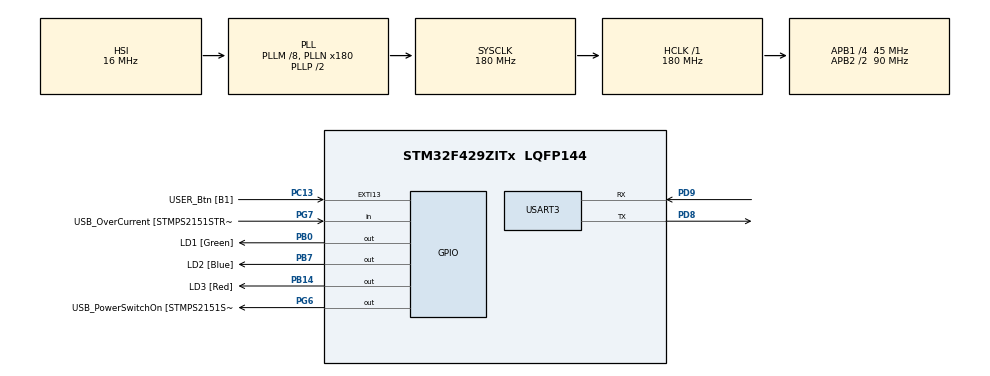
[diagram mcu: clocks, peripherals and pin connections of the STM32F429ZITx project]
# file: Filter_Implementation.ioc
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Dma.Request0=USART3_TX
Dma.Request1=USART3_RX
Dma.USART3_RX.1.Direction=DMA_PERIPH_TO_MEMORY
Dma.USART3_RX.1.FIFOMode=DMA_FIFOMODE_DISABLE
Dma.USART3_RX.1.Instance=DMA1_Stream1
Dma.USART3_RX.1.MemDataAlignment=DMA_MDATAALIGN_BYTE
Dma.USART3_RX.1.MemInc=DMA_MINC_ENABLE
Dma.USART3_RX.1.Mode=DMA_NORMAL
Dma.USART3_RX.1.PeriphDataAlignment=DMA_PDATAALIGN_BYTE
Dma.USART3_RX.1.PeriphInc=DMA_PINC_DISABLE
Dma.USART3_RX.1.Priority=DMA_PRIORITY_LOW
Dma.USART3_TX.0.Direction=DMA_MEMORY_TO_PERIPH
Dma.USART3_TX.0.FIFOMode=DMA_FIFOMODE_DISABLE
Dma.USART3_TX.0.Instance=DMA1_Stream3
Dma.USART3_TX.0.MemDataAlignment=DMA_MDATAALIGN_BYTE
Dma.USART3_TX.0.MemInc=DMA_MINC_ENABLE
Dma.USART3_TX.0.Mode=DMA_NORMAL
Dma.USART3_TX.0.PeriphDataAlignment=DMA_PDATAALIGN_BYTE
Dma.USART3_TX.0.PeriphInc=DMA_PINC_DISABLE
Dma.USART3_TX.0.Priority=DMA_PRIORITY_LOW
Mcu.Family=STM32F4
Mcu.Name=STM32F429ZITx
Mcu.Package=LQFP144
NVIC.DMA1_Stream1_IRQn=true\:0\:0\:false\:false\:true\:false\:true\:true
NVIC.DMA1_Stream3_IRQn=true\:0\:0\:false\:false\:true\:false\:true\:true
NVIC.PriorityGroup=NVIC_PRIORITYGROUP_4
NVIC.TIM1_UP_TIM10_IRQn=true\:0\:0\:false\:false\:true\:true\:true\:true
NVIC.USART3_IRQn=true\:0\:0\:false\:false\:true\:true\:true\:true
PB0.GPIO_Label=LD1 [Green]
PB0.Signal=GPIO_Output
PB14.GPIO_Label=LD3 [Red]
PB14.Signal=GPIO_Output
PB7.GPIO_Label=LD2 [Blue]
PB7.Signal=GPIO_Output
PC13.GPIO_Label=USER_Btn [B1]
PC13.Signal=GPXTI13
PD8.Mode=Asynchronous
PD8.Signal=USART3_TX
PD9.Mode=Asynchronous
PD9.Signal=USART3_RX
PG6.GPIO_Label=USB_PowerSwitchOn [STMPS2151STR_EN]
PG6.Signal=GPIO_Output
PG7.GPIO_Label=USB_OverCurrent [STMPS2151STR_FAULT]
PG7.Signal=GPIO_Input
ProjectManager.HeapSize=0x200
ProjectManager.StackSize=0x400
ProjectManager.TargetToolchain=STM32CubeIDE
RCC.48MHZClocksFreq_Value=90000000
RCC.AHBFreq_Value=180000000
RCC.APB1CLKDivider=RCC_HCLK_DIV4
RCC.APB1Freq_Value=45000000
RCC.APB1TimFreq_Value=90000000
RCC.APB2CLKDivider=RCC_HCLK_DIV2
RCC.APB2Freq_Value=90000000
RCC.APB2TimFreq_Value=180000000
RCC.CortexFreq_Value=180000000
RCC.HCLKFreq_Value=180000000
RCC.HSE_VALUE=8000000
RCC.HSI_VALUE=16000000
RCC.LSE_VALUE=32768
RCC.PLLM=8
RCC.PLLMUL=RCC_PLL_MUL9
RCC.PLLN=180
RCC.PRESCALERUSB=RCC_USBCLKSOURCE_PLL_DIV1_5
RCC.SYSCLKFreq_VALUE=180000000
RCC.SYSCLKSource=RCC_SYSCLKSOURCE_PLLCLK
RCC.SYSCLKSourceVirtual=RCC_SYSCLKSOURCE_PLLCLK
RCC.USBFreq_Value=48000000
RCC.VCOOutputFreq_Value=360000000
TIM1.AutoReloadPreload=TIM_AUTORELOAD_PRELOAD_ENABLE
TIM1.Period=1800 - 1
USART3.VirtualMode=VM_ASYNC
VP_TIM1_VS_ClockSourceINT.Mode=Internal
board=NUCLEO-F429ZI

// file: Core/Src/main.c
/* USER CODE BEGIN Header */
/**
  ******************************************************************************
  * @file           : main.c
  * @brief          : Main program body
  ******************************************************************************
  * @attention
  *
  * Copyright (c) 2025 STMicroelectronics.
  * All rights reserved.
  *
  * This software is licensed under terms that can be found in the LICENSE file
  * in the root directory of this software component.
  * If no LICENSE file comes with this software, it is provided AS-IS.
  *
  ******************************************************************************
  */
/* USER CODE END Header */
#include "main.h"

/* USER CODE BEGIN Includes */
#include <stdio.h>
#include <math.h>
#include "sfra.h"
#include "filter.h"

/* USER CODE END Includes */

TIM_HandleTypeDef htim1;

UART_HandleTypeDef huart3;
DMA_HandleTypeDef hdma_usart3_tx;
DMA_HandleTypeDef hdma_usart3_rx;

void SystemClock_Config(void);
static void MX_GPIO_Init(void);
static void MX_DMA_Init(void);
static void MX_USART3_UART_Init(void);
static void MX_TIM1_Init(void);

int main(void)
{

  /* MCU Configuration--------------------------------------------------------*/

  /* Reset of all peripherals, Initializes the Flash interface and the Systick. */
  HAL_Init();

  /* Configure the system clock */
  SystemClock_Config();

  /* Initialize all configured peripherals */
  MX_GPIO_Init();
  MX_DMA_Init();
  MX_USART3_UART_Init();
  MX_TIM1_Init();
  /* USER CODE BEGIN 2 */

//  lpf_init(ac_lpf_p, 200.0f, 100e3f);
//  pi_init(ac_pi_p, 2.0f, 500.0f, 100e3f);
//  pd_init(ac_pd_p, 2.0f, 0.002f, 100e3f);
//  sfra_init(100e3f, 5.0f, 1.54119f, 10.0f);
  sec_order_init(ac_2nd_p, 1000.0f, 0.707f, 100e3f);

  HAL_TIM_Base_Start_IT(&htim1);
  HAL_Delay(1000);
  HAL_UART_Receive_DMA(&huart3, rx_buffer, 3U);
  /* USER CODE END 2 */

  /* Infinite loop */
  /* USER CODE BEGIN WHILE */
  while (1)
  {
	  sfra_update();
    /* USER CODE END WHILE */

  }
}

void SystemClock_Config(void)
{
  RCC_OscInitTypeDef RCC_OscInitStruct = {0};
  RCC_ClkInitTypeDef RCC_ClkInitStruct = {0};

  /** Configure the main internal regulator output voltage
  */
  __HAL_RCC_PWR_CLK_ENABLE();
  __HAL_PWR_VOLTAGESCALING_CONFIG(PWR_REGULATOR_VOLTAGE_SCALE1);

  /** Initializes the RCC Oscillators according to the specified parameters
  * in the RCC_OscInitTypeDef structure.
  */
  RCC_OscInitStruct.OscillatorType = RCC_OSCILLATORTYPE_HSI;
  RCC_OscInitStruct.HSIState = RCC_HSI_ON;
  RCC_OscInitStruct.HSICalibrationValue = RCC_HSICALIBRATION_DEFAULT;
  RCC_OscInitStruct.PLL.PLLState = RCC_PLL_ON;
  RCC_OscInitStruct.PLL.PLLSource = RCC_PLLSOURCE_HSI;
  RCC_OscInitStruct.PLL.PLLM = 8;
  RCC_OscInitStruct.PLL.PLLN = 180;
  RCC_OscInitStruct.PLL.PLLP = RCC_PLLP_DIV2;
  RCC_OscInitStruct.PLL.PLLQ = 4;
  if (HAL_RCC_OscConfig(&RCC_OscInitStruct) != HAL_OK)
  {
    Error_Handler();
  }

  /** Activate the Over-Drive mode
  */
  if (HAL_PWREx_EnableOverDrive() != HAL_OK)
  {
    Error_Handler();
  }

  /** Initializes the CPU, AHB and APB buses clocks
  */
  RCC_ClkInitStruct.ClockType = RCC_CLOCKTYPE_HCLK|RCC_CLOCKTYPE_SYSCLK
                              |RCC_CLOCKTYPE_PCLK1|RCC_CLOCKTYPE_PCLK2;
  RCC_ClkInitStruct.SYSCLKSource = RCC_SYSCLKSOURCE_PLLCLK;
  RCC_ClkInitStruct.AHBCLKDivider = RCC_SYSCLK_DIV1;
  RCC_ClkInitStruct.APB1CLKDivider = RCC_HCLK_DIV4;
  RCC_ClkInitStruct.APB2CLKDivider = RCC_HCLK_DIV2;

  if (HAL_RCC_ClockConfig(&RCC_ClkInitStruct, FLASH_LATENCY_5) != HAL_OK)
  {
    Error_Handler();
  }
}

static void MX_TIM1_Init(void)
{

  TIM_ClockConfigTypeDef sClockSourceConfig = {0};
  TIM_MasterConfigTypeDef sMasterConfig = {0};

  htim1.Instance = TIM1;
  htim1.Init.Prescaler = 0;
  htim1.Init.CounterMode = TIM_COUNTERMODE_UP;
  htim1.Init.Period = 1800 - 1;
  htim1.Init.ClockDivision = TIM_CLOCKDIVISION_DIV1;
  htim1.Init.RepetitionCounter = 0;
  htim1.Init.AutoReloadPreload = TIM_AUTORELOAD_PRELOAD_ENABLE;
  if (HAL_TIM_Base_Init(&htim1) != HAL_OK)
  {
    Error_Handler();
  }
  sClockSourceConfig.ClockSource = TIM_CLOCKSOURCE_INTERNAL;
  if (HAL_TIM_ConfigClockSource(&htim1, &sClockSourceConfig) != HAL_OK)
  {
    Error_Handler();
  }
  sMasterConfig.MasterOutputTrigger = TIM_TRGO_RESET;
  sMasterConfig.MasterSlaveMode = TIM_MASTERSLAVEMODE_DISABLE;
  if (HAL_TIMEx_MasterConfigSynchronization(&htim1, &sMasterConfig) != HAL_OK)
  {
    Error_Handler();
  }

}

static void MX_USART3_UART_Init(void)
{

  huart3.Instance = USART3;
  huart3.Init.BaudRate = 115200;
  huart3.Init.WordLength = UART_WORDLENGTH_8B;
  huart3.Init.StopBits = UART_STOPBITS_1;
  huart3.Init.Parity = UART_PARITY_NONE;
  huart3.Init.Mode = UART_MODE_TX_RX;
  huart3.Init.HwFlowCtl = UART_HWCONTROL_NONE;
  huart3.Init.OverSampling = UART_OVERSAMPLING_16;
  if (HAL_UART_Init(&huart3) != HAL_OK)
  {
    Error_Handler();
  }

}

static void MX_DMA_Init(void)
{

  /* DMA controller clock enable */
  __HAL_RCC_DMA1_CLK_ENABLE();

  /* DMA interrupt init */
  /* DMA1_Stream1_IRQn interrupt configuration */
  HAL_NVIC_SetPriority(DMA1_Stream1_IRQn, 0, 0);
  HAL_NVIC_EnableIRQ(DMA1_Stream1_IRQn);
  /* DMA1_Stream3_IRQn interrupt configuration */
  HAL_NVIC_SetPriority(DMA1_Stream3_IRQn, 0, 0);
  HAL_NVIC_EnableIRQ(DMA1_Stream3_IRQn);

}

static void MX_GPIO_Init(void)
{
  GPIO_InitTypeDef GPIO_InitStruct = {0};

  /* GPIO Ports Clock Enable */
  __HAL_RCC_GPIOC_CLK_ENABLE();
  __HAL_RCC_GPIOB_CLK_ENABLE();
  __HAL_RCC_GPIOD_CLK_ENABLE();
  __HAL_RCC_GPIOG_CLK_ENABLE();

  /*Configure GPIO pin Output Level */
  HAL_GPIO_WritePin(GPIOB, LD1_Pin|LD3_Pin|LD2_Pin, GPIO_PIN_RESET);

  /*Configure GPIO pin Output Level */
  HAL_GPIO_WritePin(USB_PowerSwitchOn_GPIO_Port, USB_PowerSwitchOn_Pin, GPIO_PIN_RESET);

  /*Configure GPIO pin : USER_Btn_Pin */
  GPIO_InitStruct.Pin = USER_Btn_Pin;
  GPIO_InitStruct.Mode = GPIO_MODE_IT_RISING;
  GPIO_InitStruct.Pull = GPIO_NOPULL;
  HAL_GPIO_Init(USER_Btn_GPIO_Port, &GPIO_InitStruct);

  /*Configure GPIO pins : LD1_Pin LD3_Pin LD2_Pin */
  GPIO_InitStruct.Pin = LD1_Pin|LD3_Pin|LD2_Pin;
  GPIO_InitStruct.Mode = GPIO_MODE_OUTPUT_PP;
  GPIO_InitStruct.Pull = GPIO_NOPULL;
  GPIO_InitStruct.Speed = GPIO_SPEED_FREQ_LOW;
  HAL_GPIO_Init(GPIOB, &GPIO_InitStruct);

  /*Configure GPIO pin : USB_PowerSwitchOn_Pin */
  GPIO_InitStruct.Pin = USB_PowerSwitchOn_Pin;
  GPIO_InitStruct.Mode = GPIO_MODE_OUTPUT_PP;
  GPIO_InitStruct.Pull = GPIO_NOPULL;
  GPIO_InitStruct.Speed = GPIO_SPEED_FREQ_LOW;
  HAL_GPIO_Init(USB_PowerSwitchOn_GPIO_Port, &GPIO_InitStruct);

  /*Configure GPIO pin : USB_OverCurrent_Pin */
  GPIO_InitStruct.Pin = USB_OverCurrent_Pin;
  GPIO_InitStruct.Mode = GPIO_MODE_INPUT;
  GPIO_InitStruct.Pull = GPIO_NOPULL;
  HAL_GPIO_Init(USB_OverCurrent_GPIO_Port, &GPIO_InitStruct);

}

/* USER CODE BEGIN 4 */

int _write(int file, char *ptr, int len)
{
  (void)file;
	  HAL_UART_Transmit(&huart3, (const uint8_t *)ptr, len, HAL_MAX_DELAY);
  return len;
}

/* USER CODE END 4 */

void Error_Handler(void)
{
  __disable_irq();
  while (1)
  {
  }
}
